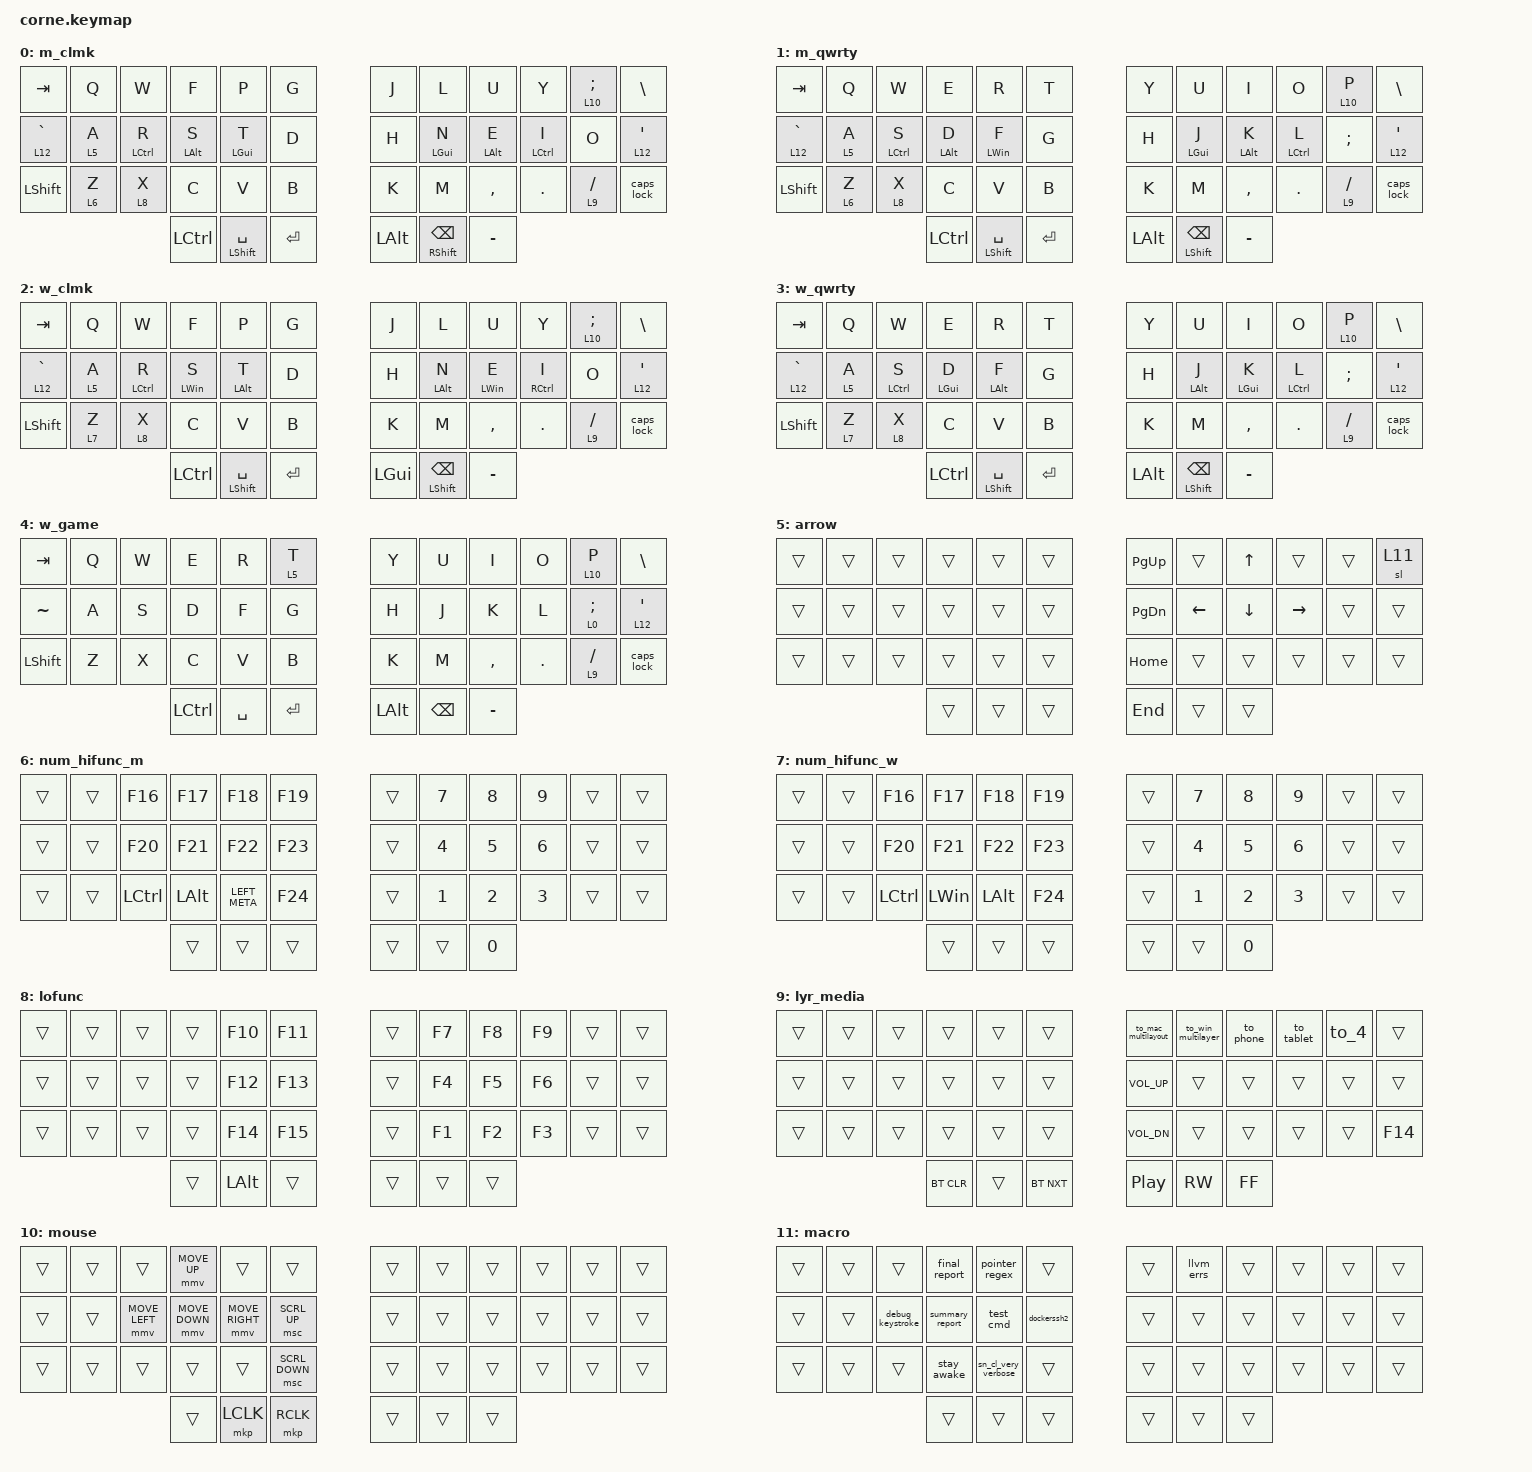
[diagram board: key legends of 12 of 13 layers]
/*
 * Copyright (c) 2020 The ZMK Contributors
 *
 * SPDX-License-Identifier: MIT
 */

#include <dt-bindings/zmk/mouse.h>
#include <behaviors.dtsi>
#include <dt-bindings/zmk/bt.h>
#include <dt-bindings/zmk/keys.h>
#include <dt-bindings/zmk/pointing.h>

&lt {
    tapping-term-ms = <175>;
    quick-tap-ms = <150>;
    flavor = "tap-preferred";
};

&mt {
    flavor = "tap-preferred";
    tapping-term-ms = <175>;
    quick-tap-ms = <150>;
};

/ {
    macros {
        to_mac_colemak: to_mac_colemak {
            compatible = "zmk,behavior-macro";
            #binding-cells = <0>;
            bindings = <&to 0 &bt BT_SEL 0>;
            label = "TO_MAC_COLEMAC";
        };

        to_mac_qwerty: to_mac_qwerty {
            compatible = "zmk,behavior-macro";
            #binding-cells = <0>;
            bindings = <&to 1 &bt BT_SEL 0>;
            label = "TO_MAC_QWERTY";
        };

        to_win_colemak: to_win_colemak {
            compatible = "zmk,behavior-macro";
            #binding-cells = <0>;
            bindings = <&to 2 &bt BT_SEL 1>;
            label = "TO_WIN_COLEMAK";
        };

        to_win_qwerty: to_win_qwerty {
            compatible = "zmk,behavior-macro";
            #binding-cells = <0>;
            bindings = <&to 3 &bt BT_SEL 1>;
            label = "TO_WIN_QWERTY";
        };

        to_phone_colemak: to_phone_colemak {
            compatible = "zmk,behavior-macro";
            #binding-cells = <0>;
            bindings = <&to 2 &bt BT_SEL 2>;
            label = "TO_PHONE_COLEMAK";
        };

        to_tablet_colemak: to_tablet_colemak {
            compatible = "zmk,behavior-macro";
            #binding-cells = <0>;
            bindings = <&to 2 &bt BT_SEL 3>;
            label = "TO_TABLET_COLEMAK";
        };

        caps_long_press: caps_long_press {
            compatible = "zmk,behavior-macro";
            #binding-cells = <0>;
            bindings = <&kp CAPSLOCK>;
            label = "CAPS_LONG_PRESS";
            tap-ms = <150>;
        };

        debug_keystroke: debug_keystroke {
            compatible = "zmk,behavior-macro";
            #binding-cells = <0>;
            bindings =
                <&macro_tap_time 1>,
                <&none &kp LS(R) &kp LS(A) &kp LS(I) &kp LS(L) &kp UNDER &kp LS(D) &kp LS(E) &kp LS(B) &kp LS(U) &kp LS(G) &kp LPAR &kp RPAR &kp SEMI &kp LEFT &kp LEFT>;

            label = "DEBUG";
        };

        test_cmd: test_cmd {
            compatible = "zmk,behavior-macro";
            #binding-cells = <0>;
            bindings =
                <&macro_tap_time 1>,
                <&none &kp T &kp E &kp S &kp T &kp SPACE &kp T &kp H &kp I &kp S &kp SPACE &kp P &kp L &kp E &kp A &kp S &kp E &kp SPACE &kp T &kp E &kp S &kp T &kp SPACE &kp T &kp H &kp I &kp S &kp SPACE &kp R &kp D &kp U>;

            label = "TEST_CMD";
        };

        stay_awake: stay_awake {
            compatible = "zmk,behavior-macro";
            #binding-cells = <0>;
            bindings =
                <&macro_tap_time 1>,
                <&kp C &kp A &kp F &kp F &kp E &kp I &kp N &kp A &kp T &kp E &kp SPACE &kp MINUS &kp D>;

            label = "STAY_AWAKE";
        };

        llvm_errs: llvm_errs {
            compatible = "zmk,behavior-macro";
            #binding-cells = <0>;
            bindings =
                <&macro_tap_time 1>,
                <&none &kp L &kp L &kp V &kp M &kp COLON &kp COLON &kp E &kp R &kp R &kp S &kp LPAR &kp RPAR &kp SPACE &kp LT &kp LT &kp SPACE &kp SPACE &kp LT &kp LT &kp SPACE &kp DQT &kp BSLH &kp N &kp DQT &kp SEMI &kp LC(LEFT) &kp LC(LEFT) &kp LC(LEFT) &kp LC(LEFT) &kp LEFT>;

            label = "LLVM_ERRS";
        };

        sn_cl_very_verbose: sn_cl_very_verbose {
            compatible = "zmk,behavior-macro";
            #binding-cells = <0>;
            bindings =
                <&macro_tap_time 1>,
                <&none &kp S &kp N &kp COLON &kp COLON &kp C &kp L &kp UNDER &kp V &kp E &kp R &kp Y &kp UNDER &kp V &kp E &kp R &kp B &kp O &kp S &kp E &kp SPACE &kp EQUAL &kp SPACE &kp T &kp R &kp U &kp E &kp SEMI>;

            label = "SN_CL_VERY_VERBOSE";
        };

        dockerssh2: dockerssh2 {
            compatible = "zmk,behavior-macro";
            #binding-cells = <0>;
            bindings =
                <&macro_tap_time 1>,
                <&none &kp B &kp A &kp S &kp H &kp SPACE &kp TILDE &kp FSLH &kp S &kp C &kp R &kp I &kp P &kp T &kp S &kp FSLH &kp D &kp O &kp C &kp K &kp E &kp R &kp UNDER &kp S &kp S &kp H &kp N2 &kp DOT &kp S &kp H &kp RET>;

            label = "DOCKERSSH2";
        };

        final_report: final_report {
            compatible = "zmk,behavior-macro";
            #binding-cells = <0>;
            bindings =
                <&macro_wait_time 1>,
                <&none &kp RG(R) &kp R &kp A &kp I &kp L &kp UNDER &kp G &kp E &kp N &kp RET &kp ENTER &kp RG(R) &kp R &kp E &kp P &kp O &kp R &kp T &kp S &kp RET &kp ENTER &kp RG(R) &kp LS(O) &kp U &kp T &kp P &kp U &kp T &kp UNDER &kp S &kp U &kp M &kp M &kp A &kp R &kp Y &kp RET &kp RET>;

            label = "FINAL_REPORT";
        };

        summary_report: summary_report {
            compatible = "zmk,behavior-macro";
            #binding-cells = <0>;
            bindings =
                <&macro_wait_time 1>,
                <&none &kp RG(R) &kp R &kp A &kp I &kp L &kp UNDER &kp G &kp E &kp N &kp RET &kp ENTER &kp RG(R) &kp R &kp E &kp P &kp O &kp R &kp T &kp S &kp RET &kp ENTER &kp RG(R) &kp LS(S) &kp LS(I) &kp N &kp P &kp U &kp T &kp RET &kp RET>;

            label = "SUMMARY_REPORT";
        };

        to_win_game: to_win_game {
            compatible = "zmk,behavior-macro";
            #binding-cells = <0>;
            bindings = <&bt BT_SEL 1 &to 4>;
            label = "TO_WIN_GAME";
        };

        pointer_regex: pointer_regex {
            compatible = "zmk,behavior-macro";
            #binding-cells = <0>;
            bindings =
                <&macro_wait_time 1>,
                <&none &kp N0 &kp X &kp LBKT &kp N0 &kp MINUS &kp N9 &kp A &kp MINUS &kp F &kp RBKT &kp PLUS>;

            label = "POINTER_REGEX";
        };
    };

    behaviors {
        to_mac_multilayout: to_mac_multilayout {
            compatible = "zmk,behavior-tap-dance";
            label = "TO_MAC_MULTILAYOUT";
            #binding-cells = <0>;
            bindings = <&to_mac_colemak>, <&to_mac_qwerty>, <&bt BT_DISC 0>;
        };

        to_win_multilayer: to_win_multilayer {
            compatible = "zmk,behavior-tap-dance";
            label = "TO_WIN_MULTILAYER";
            #binding-cells = <0>;
            bindings =
                <&to_win_colemak>,
                <&to_win_qwerty>,
                <&to_win_game>,
                <&bt BT_DISC 1>;
        };

        to_phone: to_phone {
            compatible = "zmk,behavior-tap-dance";
            label = "TO_PHONE";
            #binding-cells = <0>;
            bindings = <&to_phone_colemak>, <&bt BT_DISC 2>;
        };

        to_tablet: to_tablet {
            compatible = "zmk,behavior-tap-dance";
            label = "TO_TABLET";
            #binding-cells = <0>;
            bindings = <&to_tablet_colemak>, <&bt BT_DISC 3>;
        };

        to_4: to_4 {
            compatible = "zmk,behavior-tap-dance";
            label = "TO_4";
            #binding-cells = <0>;
            bindings = <&to_win_colemak>, <&bt BT_DISC 4>;
        };

        caps_lock: caps_lock {
            compatible = "zmk,behavior-tap-dance";
            label = "CAPS_LOCK";
            #binding-cells = <0>;
            bindings = <&kp LEFT_SHIFT>, <&caps_long_press>;

            tapping-term-ms = <200>;
        };
    };

    combos {
        compatible = "zmk,combos";

        combo_home {
            bindings = <&kp HOME>;
            key-positions = <39 40>;
        };

        combo_end {
            bindings = <&kp END>;
            key-positions = <40 41>;
        };

        combo_pgup {
            bindings = <&kp PG_UP>;
            key-positions = <6 18>;
        };

        combo_pgdn {
            bindings = <&kp PAGE_DOWN>;
            key-positions = <30 18>;
        };

        combo_esc {
            bindings = <&kp ESCAPE>;
            key-positions = <0 1>;
        };

        combo_del {
            bindings = <&kp DELETE>;
            key-positions = <10 11>;
        };

        combo_mac {
            bindings = <&kp LEFT_WIN>;
            key-positions = <36 37>;
        };
    };

    keymap {
        compatible = "zmk,keymap";

        m_clmk {
            display-name = "m_clmk";
            bindings = <
&kp TAB       &kp Q    &kp W        &kp F           &kp P                 &kp G      &kp J     &kp L                      &kp U           &kp Y        &lt 10 SEMICOLON  &kp BSLH
&lt 12 GRAVE  &lt 5 A  &mt LCTRL R  &mt LEFT_ALT S  &mt LEFT_GUI T        &kp D      &kp H     &mt LEFT_GUI N             &mt LEFT_ALT E  &mt LCTRL I  &kp O             &lt 12 SQT
&kp LSHFT     &lt 6 Z  &lt 8 X      &kp C           &kp V                 &kp B      &kp K     &kp M                      &kp COMMA       &kp DOT      &lt 9 SLASH       &caps_lock
                                    &kp LCTRL       &mt LEFT_SHIFT SPACE  &kp RET    &kp LALT  &mt RIGHT_SHIFT BACKSPACE  &kp MINUS
            >;
        };

        m_qwrty {
            display-name = "m_qwrty";
            bindings = <
&kp TAB       &kp Q    &kp W        &kp E           &kp R                 &kp T        &kp Y     &kp U                     &kp I           &kp O        &lt 10 P       &kp BSLH
&lt 12 GRAVE  &lt 5 A  &mt LCTRL S  &mt LEFT_ALT D  &mt LEFT_WIN F        &kp G        &kp H     &mt LEFT_GUI J            &mt LEFT_ALT K  &mt LCTRL L  &kp SEMICOLON  &lt 12 SQT
&kp LSHFT     &lt 6 Z  &lt 8 X      &kp C           &kp V                 &kp B        &kp K     &kp M                     &kp COMMA       &kp DOT      &lt 9 FSLH     &caps_lock
                                    &kp LCTRL       &mt LEFT_SHIFT SPACE  &kp ENTER    &kp LALT  &mt LEFT_SHIFT BACKSPACE  &kp MINUS
            >;
        };

        w_clmk {
            display-name = "w_clmk";
            bindings = <
&kp TAB       &kp Q    &kp W        &kp F           &kp P                 &kp G      &kp J     &kp L                     &kp U           &kp Y        &lt 10 SEMI  &kp BSLH
&lt 12 GRAVE  &lt 5 A  &mt LCTRL R  &mt LEFT_WIN S  &mt LEFT_ALT T        &kp D      &kp H     &mt LEFT_ALT N            &mt LEFT_WIN E  &mt RCTRL I  &kp O        &lt 12 SQT
&kp LSHFT     &lt 7 Z  &lt 8 X      &kp C           &kp V                 &kp B      &kp K     &kp M                     &kp COMMA       &kp DOT      &lt 9 FSLH   &caps_lock
                                    &kp LCTRL       &mt LEFT_SHIFT SPACE  &kp RET    &kp LGUI  &mt LEFT_SHIFT BACKSPACE  &kp MINUS
            >;
        };

        w_qwrty {
            display-name = "w_qwrty";
            bindings = <
&kp TAB       &kp Q    &kp W        &kp E           &kp R                 &kp T      &kp Y     &kp U                     &kp I           &kp O        &lt 10 P    &kp BSLH
&lt 12 GRAVE  &lt 5 A  &mt LCTRL S  &mt LEFT_GUI D  &mt LEFT_ALT F        &kp G      &kp H     &mt LEFT_ALT J            &mt LEFT_GUI K  &mt LCTRL L  &kp SEMI    &lt 12 SQT
&kp LSHFT     &lt 7 Z  &lt 8 X      &kp C           &kp V                 &kp B      &kp K     &kp M                     &kp COMMA       &kp DOT      &lt 9 FSLH  &caps_lock
                                    &kp LCTRL       &mt LEFT_SHIFT SPACE  &kp RET    &kp LALT  &mt LEFT_SHIFT BACKSPACE  &kp MINUS
            >;
        };

        w_game {
            display-name = "w_game";
            bindings = <
&kp TAB    &kp Q  &kp W  &kp E      &kp R      &lt 5 T    &kp Y     &kp U     &kp I      &kp O    &lt 10 P    &kp BSLH
&kp TILDE  &kp A  &kp S  &kp D      &kp F      &kp G      &kp H     &kp J     &kp K      &kp L    &lt 0 SEMI  &lt 12 SQT
&kp LSHFT  &kp Z  &kp X  &kp C      &kp V      &kp B      &kp K     &kp M     &kp COMMA  &kp DOT  &lt 9 FSLH  &caps_lock
                         &kp LCTRL  &kp SPACE  &kp RET    &kp LALT  &kp BSPC  &kp MINUS
            >;
        };

        arrow {
            display-name = "arrow";
            bindings = <
&trans  &trans  &trans  &trans  &trans  &trans    &kp PG_UP      &trans    &kp UP    &trans     &trans  &sl 11
&trans  &trans  &trans  &trans  &trans  &trans    &kp PAGE_DOWN  &kp LEFT  &kp DOWN  &kp RIGHT  &trans  &trans
&trans  &trans  &trans  &trans  &trans  &trans    &kp HOME       &trans    &trans    &trans     &trans  &trans
                        &trans  &trans  &trans    &kp END        &trans    &trans
            >;
        };

        num_hifunc_m {
            display-name = "num_hifunc_m";
            bindings = <
&trans  &trans  &kp F16    &kp F17       &kp F18        &kp F19    &trans  &kp N7  &kp N8  &kp N9  &trans  &trans
&trans  &trans  &kp F20    &kp F21       &kp F22        &kp F23    &trans  &kp N4  &kp N5  &kp N6  &trans  &trans
&trans  &trans  &kp LCTRL  &kp LEFT_ALT  &kp LEFT_META  &kp F24    &trans  &kp N1  &kp N2  &kp N3  &trans  &trans
                           &trans        &trans         &trans     &trans  &trans  &kp N0
            >;
        };

        num_hifunc_w {
            display-name = "num_hifunc_w";
            bindings = <
&trans  &trans  &kp F16    &kp F17       &kp F18       &kp F19    &trans  &kp N7  &kp N8  &kp N9  &trans  &trans
&trans  &trans  &kp F20    &kp F21       &kp F22       &kp F23    &trans  &kp N4  &kp N5  &kp N6  &trans  &trans
&trans  &trans  &kp LCTRL  &kp LEFT_WIN  &kp LEFT_ALT  &kp F24    &trans  &kp N1  &kp N2  &kp N3  &trans  &trans
                           &trans        &trans        &trans     &trans  &trans  &kp N0
            >;
        };

        low_func {
            display-name = "lofunc";
            bindings = <
&trans  &trans  &trans  &trans  &kp F10       &kp F11    &trans  &kp F7  &kp F8  &kp F9  &trans  &trans
&trans  &trans  &trans  &trans  &kp F12       &kp F13    &trans  &kp F4  &kp F5  &kp F6  &trans  &trans
&trans  &trans  &trans  &trans  &kp F14       &kp F15    &trans  &kp F1  &kp F2  &kp F3  &trans  &trans
                        &trans  &kp LEFT_ALT  &trans     &trans  &trans  &trans
            >;
        };

        lyr_and_media {
            display-name = "lyr_media";
            bindings = <
&trans  &trans  &trans  &trans      &trans  &trans        &to_mac_multilayout  &to_win_multilayer  &to_phone  &to_tablet  &to_4   &trans
&trans  &trans  &trans  &trans      &trans  &trans        &kp C_VOL_UP         &trans              &trans     &trans      &trans  &trans
&trans  &trans  &trans  &trans      &trans  &trans        &kp C_VOL_DN         &trans              &trans     &trans      &trans  &kp F14
                        &bt BT_CLR  &trans  &bt BT_NXT    &kp C_PLAY_PAUSE     &kp C_RW            &kp C_FF
            >;
        };

        mouse {
            display-name = "mouse";
            bindings = <
&trans  &trans  &trans          &mmv MOVE_UP    &trans           &trans            &trans  &trans  &trans  &trans  &trans  &trans
&trans  &trans  &mmv MOVE_LEFT  &mmv MOVE_DOWN  &mmv MOVE_RIGHT  &msc SCRL_UP      &trans  &trans  &trans  &trans  &trans  &trans
&trans  &trans  &trans          &trans          &trans           &msc SCRL_DOWN    &trans  &trans  &trans  &trans  &trans  &trans
                                &trans          &mkp LCLK        &mkp RCLK         &trans  &trans  &trans
            >;
        };

        macros {
            display-name = "macro";
            bindings = <
&trans  &trans  &trans            &final_report    &pointer_regex       &trans         &trans  &llvm_errs  &trans  &trans  &trans  &trans
&trans  &trans  &debug_keystroke  &summary_report  &test_cmd            &dockerssh2    &trans  &trans      &trans  &trans  &trans  &trans
&trans  &trans  &trans            &stay_awake      &sn_cl_very_verbose  &trans         &trans  &trans      &trans  &trans  &trans  &trans
                                  &trans           &trans               &trans         &trans  &trans      &trans
            >;
        };

        special_chars {
            display-name = "special_char";
            bindings = <
&kp ESCAPE  &kp EXCL  &kp AT  &kp HASH  &kp DLLR  &kp PRCNT    &kp CARET  &kp AMPS  &kp STAR   &kp LPAR  &kp RPAR  &kp DELETE
&trans      &trans    &trans  &trans    &trans    &kp LBKT     &kp RBKT   &trans    &trans     &trans    &trans    &trans
&trans      &trans    &trans  &trans    &trans    &trans       &trans     &trans    &trans     &trans    &trans    &trans
                              &trans    &trans    &trans       &trans     &trans    &kp EQUAL
            >;
        };
    };
};
